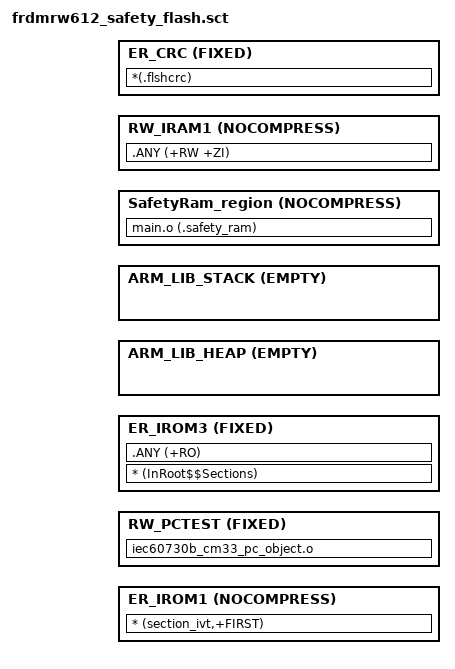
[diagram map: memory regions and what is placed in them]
#!armclang --target=arm-arm-none-eabi -march=armv8-m.main -E -x c

/*
** ###################################################################
**     Processors:          RW612ETA2I
**                          RW612HNA2I
**                          RW612UKA2I
**
**     Compiler:            Keil ARM C/C++ Compiler
**     Reference manual:    RW61X User manual Rev. 0.95, June 2022
**     Version:             rev. 1.0, 2021-03-16
**     Build:               b231201
**
**     Abstract:
**         Linker file for the Keil ARM C/C++ Compiler
**
**     Copyright 2016 Freescale Semiconductor, Inc.
**     Copyright 2016-2023 NXP
**     SPDX-License-Identifier: BSD-3-Clause
**
**     http:                 www.nxp.com
**     mail:                 support@nxp.com
**
** ###################################################################
*/


#include "linker_config.h"

LR_IROM1 __ROM_start__ (m_flash_end)   {    ; load region size_region
  
    ER_IROM1 m_intvec_table_start NOCOMPRESS __vector_table_size__ {  ; load address = execution address
        * (section_ivt,+FIRST)
    }
	
	RW_PCTEST __PC_test_start__ FIXED __PC_test_size {

    iec60730b_cm33_pc_object.o 
    }
	
	ER_IROM3 (m_flash_start) FIXED {  ; load address = execution address
        * (InRoot$$Sections)
        .ANY (+RO)
    }
}

LR_IROM2 (+0)
{
  ARM_LIB_HEAP +0 EMPTY 0x0 {    ; Heap region growing up
  }

  ARM_LIB_STACK __BOOT_STACK_ADDRESS EMPTY -(__size_cstack__){ ; Stack region growing down
  }

  SafetyRam_region m_safety_ram_start NOCOMPRESS {
  main.o (.safety_ram)
  }
  
  RW_IRAM1 (+0) NOCOMPRESS  {  ; RW data
   .ANY (+RW +ZI)
  }
}

LR_IROM3 m_fs_flash_crc_start __size_flash_crc__{

    ; Safety-flash CRC region
    ER_CRC (m_fs_flash_crc_start) FIXED (__size_flash_crc__)
    {
        *(.flshcrc)
    }
}
